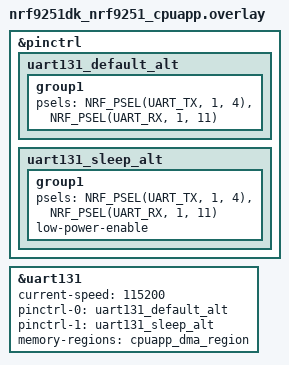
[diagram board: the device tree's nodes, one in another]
/*
 * Copyright (c) 2026 Nordic Semiconductor ASA
 *
 * SPDX-License-Identifier: LicenseRef-Nordic-5-Clause
 */

/* Test requires loopbacks:
 * - TX-RX: P1.04 - P1.11
 */

&pinctrl {
	uart131_default_alt: uart131_default_alt {
		group1 {
			psels = <NRF_PSEL(UART_TX, 1, 4)>,
				<NRF_PSEL(UART_RX, 1, 11)>;
		};
	};

	uart131_sleep_alt: uart131_sleep_alt {
		group1 {
			psels = <NRF_PSEL(UART_TX, 1, 4)>,
				<NRF_PSEL(UART_RX, 1, 11)>;
			low-power-enable;
		};
	};
};

dut: &uart131 {
	status = "okay";
	current-speed = <115200>;
	pinctrl-0 = <&uart131_default_alt>;
	pinctrl-1 = <&uart131_sleep_alt>;
	pinctrl-names = "default", "sleep";
	memory-regions = <&cpuapp_dma_region>;
};
